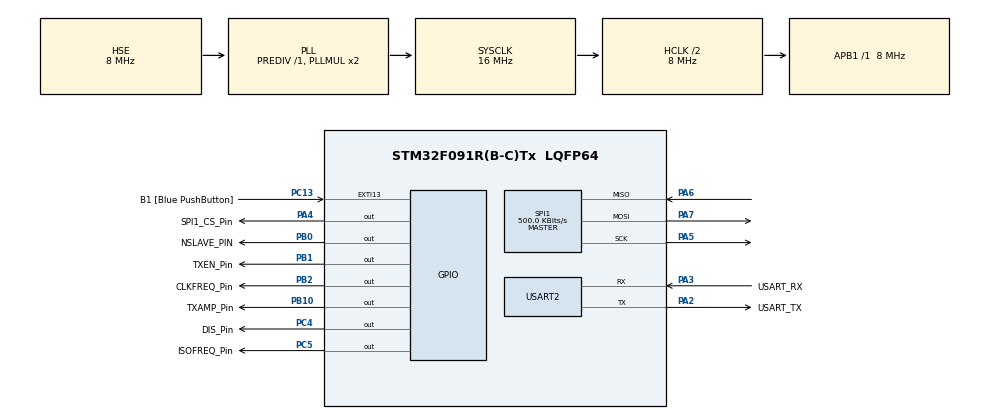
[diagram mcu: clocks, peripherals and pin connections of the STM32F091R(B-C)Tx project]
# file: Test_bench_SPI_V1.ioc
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Mcu.Family=STM32F0
Mcu.Name=STM32F091R(B-C)Tx
Mcu.Package=LQFP64
PA13.GPIO_Label=TMS
PA13.Mode=Serial_Wire
PA13.Signal=SYS_SWDIO
PA14.GPIO_Label=TCK
PA14.Mode=Serial_Wire
PA14.Signal=SYS_SWCLK
PA2.GPIO_Label=USART_TX
PA2.GPIO_Mode=GPIO_MODE_AF_PP
PA2.GPIO_PuPd=GPIO_NOPULL
PA2.GPIO_Speed=GPIO_SPEED_FREQ_LOW
PA2.Mode=Asynchronous
PA2.Signal=USART2_TX
PA3.GPIO_Label=USART_RX
PA3.GPIO_Mode=GPIO_MODE_AF_PP
PA3.GPIO_PuPd=GPIO_NOPULL
PA3.GPIO_Speed=GPIO_SPEED_FREQ_LOW
PA3.Mode=Asynchronous
PA3.Signal=USART2_RX
PA4.GPIO_Label=SPI1_CS_Pin
PA4.Signal=GPIO_Output
PA5.Mode=Full_Duplex_Master
PA5.Signal=SPI1_SCK
PA6.Mode=Full_Duplex_Master
PA6.Signal=SPI1_MISO
PA7.Mode=Full_Duplex_Master
PA7.Signal=SPI1_MOSI
PB0.GPIO_Label=NSLAVE_PIN
PB0.Signal=GPIO_Output
PB1.GPIO_Label=TXEN_Pin
PB1.Signal=GPIO_Output
PB10.GPIO_Label=TXAMP_Pin
PB10.Signal=GPIO_Output
PB2.GPIO_Label=CLKFREQ_Pin
PB2.Signal=GPIO_Output
PC13.GPIO_Label=B1 [Blue PushButton]
PC13.GPIO_ModeDefaultEXTI=GPIO_MODE_IT_FALLING
PC13.Signal=GPXTI13
PC14OSC32_IN.Mode=LSE-External-Oscillator
PC14OSC32_IN.Signal=RCC_OSC32_IN
PC15OSC32_OUT.Mode=LSE-External-Oscillator
PC15OSC32_OUT.Signal=RCC_OSC32_OUT
PC4.GPIO_Label=DIS_Pin
PC4.Signal=GPIO_Output
PC5.GPIO_Label=ISOFREQ_Pin
PC5.Signal=GPIO_Output
PF0-OSC_IN.Mode=HSE-External-Clock-Source
PF0-OSC_IN.Signal=RCC_OSC_IN
PF1-OSC_OUT.Signal=RCC_OSC_OUT
ProjectManager.HeapSize=0x200
ProjectManager.StackSize=0x400
ProjectManager.TargetToolchain=STM32CubeIDE
RCC.AHBCLKDivider=RCC_SYSCLK_DIV2
RCC.AHBFreq_Value=8000000
RCC.APB1Freq_Value=8000000
RCC.APB1TimFreq_Value=8000000
RCC.FLatency-AdvancedSettings=FLASH_LATENCY_0
RCC.HCLKFreq_Value=8000000
RCC.PLLSourceVirtual=RCC_PLLSOURCE_HSE
RCC.PREFETCH_ENABLE-AdvancedSettings=1
RCC.SYSCLKFreq_VALUE=16000000
RCC.SYSCLKSource=RCC_SYSCLKSOURCE_PLLCLK
SPI1.BaudRatePrescaler=SPI_BAUDRATEPRESCALER_16
SPI1.CRCCalculation=SPI_CRCCALCULATION_DISABLE
SPI1.CalculateBaudRate=500.0 KBits/s
SPI1.DataSize=SPI_DATASIZE_8BIT
SPI1.Direction=SPI_DIRECTION_2LINES
SPI1.Mode=SPI_MODE_MASTER
SPI1.NSSPMode=SPI_NSS_PULSE_ENABLE
SPI1.VirtualType=VM_MASTER
USART2.VirtualMode=VM_ASYNC
USART2.VirtualMode-Asynchronous=VM_ASYNC
board=NUCLEO-F091RC

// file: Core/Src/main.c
/* USER CODE BEGIN Header */
/* USER CODE END Header */
#include "main.h"
#include "spi.h"
#include "usart.h"
#include "gpio.h"

/* USER CODE BEGIN Includes */
#include "L9963E.h"
#include "L9963E_DRV.h"
#include "stm32_if.h"
/* USER CODE END Includes */

void SystemClock_Config(void);

int main(void)
{

  /* MCU Configuration--------------------------------------------------------*/

  /* Reset of all peripherals, Initializes the Flash interface and the Systick. */
  HAL_Init();

  /* USER CODE BEGIN Init */
  L9963E_Init();
  /* USER CODE END Init */

  /* Configure the system clock */
  SystemClock_Config();

  /* Initialize all configured peripherals */
  MX_GPIO_Init();
  MX_USART2_UART_Init();
  MX_SPI1_Init();

  /* Infinite loop */

}

void SystemClock_Config(void)
{
  RCC_OscInitTypeDef RCC_OscInitStruct = {0};
  RCC_ClkInitTypeDef RCC_ClkInitStruct = {0};
  RCC_PeriphCLKInitTypeDef PeriphClkInit = {0};

  /** Initializes the RCC Oscillators according to the specified parameters
  * in the RCC_OscInitTypeDef structure.
  */
  RCC_OscInitStruct.OscillatorType = RCC_OSCILLATORTYPE_HSE;
  RCC_OscInitStruct.HSEState = RCC_HSE_BYPASS;
  RCC_OscInitStruct.PLL.PLLState = RCC_PLL_ON;
  RCC_OscInitStruct.PLL.PLLSource = RCC_PLLSOURCE_HSE;
  RCC_OscInitStruct.PLL.PLLMUL = RCC_PLL_MUL2;
  RCC_OscInitStruct.PLL.PREDIV = RCC_PREDIV_DIV1;
  if (HAL_RCC_OscConfig(&RCC_OscInitStruct) != HAL_OK)
  {
    Error_Handler();
  }

  /** Initializes the CPU, AHB and APB buses clocks
  */
  RCC_ClkInitStruct.ClockType = RCC_CLOCKTYPE_HCLK|RCC_CLOCKTYPE_SYSCLK
                              |RCC_CLOCKTYPE_PCLK1;
  RCC_ClkInitStruct.SYSCLKSource = RCC_SYSCLKSOURCE_PLLCLK;
  RCC_ClkInitStruct.AHBCLKDivider = RCC_SYSCLK_DIV2;
  RCC_ClkInitStruct.APB1CLKDivider = RCC_HCLK_DIV1;

  if (HAL_RCC_ClockConfig(&RCC_ClkInitStruct, FLASH_LATENCY_0) != HAL_OK)
  {
    Error_Handler();
  }
  PeriphClkInit.PeriphClockSelection = RCC_PERIPHCLK_USART2;
  PeriphClkInit.Usart2ClockSelection = RCC_USART2CLKSOURCE_PCLK1;
  if (HAL_RCCEx_PeriphCLKConfig(&PeriphClkInit) != HAL_OK)
  {
    Error_Handler();
  }
}

void Error_Handler(void)
{
}
